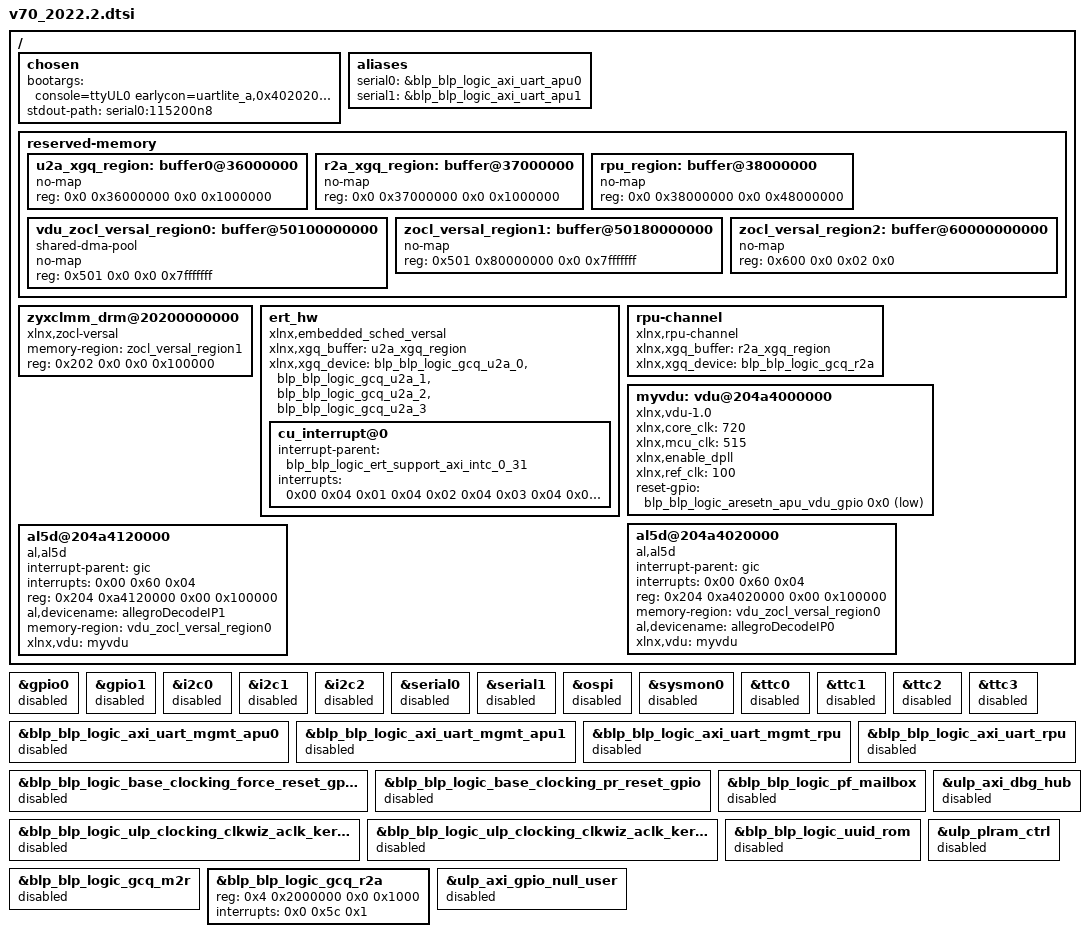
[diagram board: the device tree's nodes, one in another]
&gpio0 {
    status = "disabled";
};
&gpio1 {
    status = "disabled";
};
&i2c0 {
    status = "disabled";
};
&i2c1 {
    status = "disabled";
};
&i2c2 {
    status = "disabled";
};
&serial0 {
    status = "disabled";
};
&serial1 {
    status = "disabled";
};
&ospi {
    status = "disabled";
};
&sysmon0 {
    status = "disabled";
};
&ttc0 {
    status = "disabled";
};
&ttc1 {
    status = "disabled";
};
&ttc2 {
    status = "disabled";
};
&ttc3 {
    status = "disabled";
};
&blp_blp_logic_axi_uart_mgmt_apu0 {
    status = "disabled";
};
&blp_blp_logic_axi_uart_mgmt_apu1 {
    status = "disabled";
};
&blp_blp_logic_axi_uart_mgmt_rpu {
    status = "disabled";
};
&blp_blp_logic_axi_uart_rpu {
    status = "disabled";
};
&blp_blp_logic_base_clocking_force_reset_gpio {
    status = "disabled";
};
&blp_blp_logic_base_clocking_pr_reset_gpio {
    status = "disabled";
};
&blp_blp_logic_pf_mailbox {
    status = "disabled";
};
&blp_blp_logic_ulp_clocking_clkwiz_aclk_kernel_00 {
    status = "disabled";
};
&blp_blp_logic_ulp_clocking_clkwiz_aclk_kernel_01 {
    status = "disabled";
};
&blp_blp_logic_uuid_rom {
    status = "disabled";
};
&blp_blp_logic_gcq_m2r {
    status = "disabled";
};
&blp_blp_logic_gcq_r2a {
    reg = <0x4 0x2000000 0x0 0x1000>;
    interrupts = <0x0 0x5c 0x1>;
};
&ulp_axi_dbg_hub {
    status = "disabled";
};
&ulp_axi_gpio_null_user {
    status = "disabled";
};
&ulp_plram_ctrl {
    status = "disabled";
};
&blp_blp_logic_axi_uart_mgmt_apu0 {
    status = "disabled";
};
&blp_blp_logic_axi_uart_mgmt_apu1 {
    status = "disabled";
};
&blp_blp_logic_axi_uart_mgmt_rpu {
    status = "disabled";
};
&blp_blp_logic_axi_uart_rpu {
    status = "disabled";
};
/delete-node/ &ulp_vdu;

/ {
    chosen {
        bootargs = "console=ttyUL0  earlycon=uartlite_a,0x402020000,115200n8 clk_ignore_unused root=/dev/mmcblk0p2 rw rootwait";
        stdout-path = "serial0:115200n8";
    };

    aliases {
	/delete-property/ serial0;
	/delete-property/ serial1;
	/delete-property/ serial2;
	/delete-property/ serial3;
	/delete-property/ serial4;
	/delete-property/ serial5;
	/delete-property/ serial6;
	/delete-property/ serial7;        
	serial0 = &blp_blp_logic_axi_uart_apu0;
	serial1 = &blp_blp_logic_axi_uart_apu1;    
    };

    reserved-memory {
        #address-cells = <0x2>;
        #size-cells = <0x2>;
        ranges;

        u2a_xgq_region: buffer0@36000000 {
            no-map;
            reg = <0x0 0x36000000 0x0 0x1000000>;
        };

        r2a_xgq_region: buffer@37000000 {
            no-map;
            reg = <0x0 0x37000000 0x0 0x1000000>;
        };

	rpu_region: buffer@38000000 {
	    no-map;
	    reg = <0x0 0x38000000 0x0 0x48000000>;
	};

        vdu_zocl_versal_region0: buffer@50100000000 {
	    compatible = "shared-dma-pool";
            no-map;
            reg = <0x501 0x0 0x0 0x7fffffff>;
        };
	
        zocl_versal_region1: buffer@50180000000 {
            no-map;
            reg = <0x501 0x80000000 0x0 0x7fffffff>;
        };
        
        zocl_versal_region2: buffer@60000000000 {
            no-map;
            reg = <0x600 0x0 0x02 0x0>;
        };

    };

	zyxclmm_drm@20200000000 {
		compatible = "xlnx,zocl-versal";
		status = "okay";
		memory-region = <&zocl_versal_region1>;
		reg = <0x202 0x0 0x0 0x100000>;
	};

	ert_hw {
		compatible = "xlnx,embedded_sched_versal";
		status = "okay";
		xlnx,xgq_buffer = <&u2a_xgq_region>;
		xlnx,xgq_device = <&blp_blp_logic_gcq_u2a_0 &blp_blp_logic_gcq_u2a_1 &blp_blp_logic_gcq_u2a_2 &blp_blp_logic_gcq_u2a_3>;
		interrupt-names = "irq_sq";

		cu_interrupt@0 {
			interrupt-parent = <&blp_blp_logic_ert_support_axi_intc_0_31>;
			interrupts = <0x00 0x04 0x01 0x04 0x02 0x04 0x03 0x04 0x04 0x04 0x05 0x04 0x06 0x04 0x07 0x04 0x08 0x04 0x09 0x04 0x0a 0x04 0x0b 0x04 0x0c 0x04 0x0d 0x04 0x0e 0x04 0x0f 0x04 0x10 0x04 0x11 0x04 0x12 0x04 0x13 0x04 0x14 0x04 0x15 0x04 0x16 0x04 0x17 0x04 0x18 0x04 0x19 0x04 0x1a 0x04 0x1b 0x04 0x1c 0x04 0x1d 0x04 0x1e 0x04 0x1f 0x04>;
		};
	};

	rpu-channel {
		compatible = "xlnx,rpu-channel";
		xlnx,xgq_buffer = <&r2a_xgq_region>;
		xlnx,xgq_device = <&blp_blp_logic_gcq_r2a>;
		interrupt-names = "irq_sq";
	};

	myvdu: vdu@204a4000000 {
        	compatible = "xlnx,vdu-1.0";
        	xlnx,core_clk = <720>;
		xlnx,mcu_clk = <515>;
        	xlnx,enable_dpll;
        	xlnx,ref_clk = <100>;
		reset-gpio = <&blp_blp_logic_aresetn_apu_vdu_gpio 0x0 0x01>; 
        };

        al5d@204a4020000 {
        	compatible = "al,al5d";
        	interrupt-names = "vdu_host_interrupt0";
        	interrupt-parent = <&gic>;
		interrupts = <0x00 0x60 0x04>;
        	reg = <0x204 0xa4020000 0x00 0x100000>;
        	memory-region = <&vdu_zocl_versal_region0>;
        	al,devicename = "allegroDecodeIP0";
        	xlnx,vdu = <&myvdu>;
        };
	
	al5d@204a4120000 {
		compatible = "al,al5d";
		interrupt-names = "vdu_host_interrupt1";
		interrupt-parent = <&gic>;
		interrupts = <0x00 0x60 0x04>;
		reg = <0x204 0xa4120000 0x00 0x100000>;
		al,devicename = "allegroDecodeIP1";
		memory-region = <&vdu_zocl_versal_region0>;
		xlnx,vdu = <&myvdu>;	
	};


};
